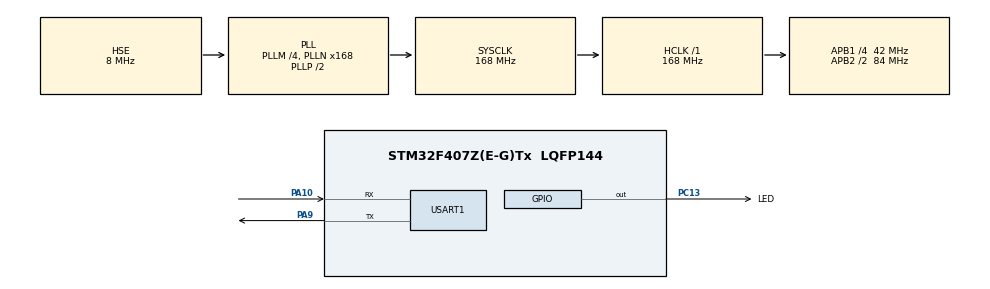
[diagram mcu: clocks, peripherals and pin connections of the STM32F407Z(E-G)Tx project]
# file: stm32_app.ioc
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Mcu.Family=STM32F4
Mcu.Name=STM32F407Z(E-G)Tx
Mcu.Package=LQFP144
NVIC.PriorityGroup=NVIC_PRIORITYGROUP_4
NVIC.USART1_IRQn=true\:5\:0\:true\:false\:true\:true\:true\:true
PA10.Mode=Asynchronous
PA10.Signal=USART1_RX
PA13.Mode=Serial_Wire
PA13.Signal=SYS_JTMS-SWDIO
PA14.Mode=Serial_Wire
PA14.Signal=SYS_JTCK-SWCLK
PA9.Mode=Asynchronous
PA9.Signal=USART1_TX
PC13-ANTI_TAMP.GPIO_Label=LED
PC13-ANTI_TAMP.Signal=GPIO_Output
PC14-OSC32_IN.Mode=LSE-External-Oscillator
PC14-OSC32_IN.Signal=RCC_OSC32_IN
PC15-OSC32_OUT.Mode=LSE-External-Oscillator
PC15-OSC32_OUT.Signal=RCC_OSC32_OUT
PH0-OSC_IN.Mode=HSE-External-Oscillator
PH0-OSC_IN.Signal=RCC_OSC_IN
PH1-OSC_OUT.Mode=HSE-External-Oscillator
PH1-OSC_OUT.Signal=RCC_OSC_OUT
ProjectManager.HeapSize=0x200
ProjectManager.StackSize=0x400
ProjectManager.TargetToolchain=MDK-ARM V5.32
RCC.48MHZClocksFreq_Value=84000000
RCC.AHBFreq_Value=168000000
RCC.APB1CLKDivider=RCC_HCLK_DIV4
RCC.APB1Freq_Value=42000000
RCC.APB1TimFreq_Value=84000000
RCC.APB2CLKDivider=RCC_HCLK_DIV2
RCC.APB2Freq_Value=84000000
RCC.APB2TimFreq_Value=168000000
RCC.CortexFreq_Value=168000000
RCC.HCLKFreq_Value=168000000
RCC.HSE_VALUE=8000000
RCC.HSI_VALUE=16000000
RCC.PLLM=4
RCC.PLLN=168
RCC.PLLSourceVirtual=RCC_PLLSOURCE_HSE
RCC.SYSCLKFreq_VALUE=168000000
RCC.SYSCLKSource=RCC_SYSCLKSOURCE_PLLCLK
RCC.VCOOutputFreq_Value=336000000
USART1.VirtualMode=VM_ASYNC
board=custom

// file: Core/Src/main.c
/* USER CODE BEGIN Header */
/**
  ******************************************************************************
  * @file           : main.c
  * @brief          : Main program body
  ******************************************************************************
  * @attention
  *
  * Copyright (c) 2026 STMicroelectronics.
  * All rights reserved.
  *
  * This software is licensed under terms that can be found in the LICENSE file
  * in the root directory of this software component.
  * If no LICENSE file comes with this software, it is provided AS-IS.
  *
  ******************************************************************************
  */
/* USER CODE END Header */
#include "main.h"
#include "usart.h"
#include "gpio.h"

/* USER CODE BEGIN Includes */
#include <stdio.h>
#include "app_upgrade.h"
/* USER CODE END Includes */

/* USER CODE BEGIN PD */
#define APP_VERSION        "1.3.0"
#define APP_BASE_ADDR      0x08020000UL

#ifndef LOG_ENABLE
    #define LOG_ENABLE  0
#endif
/* USER CODE END PD */

/* USER CODE BEGIN PM */
#if LOG_ENABLE
#define APP_LOG(fmt, ...)   printf("[APP] " fmt "\r\n", ##__VA_ARGS__)
#else
#define APP_LOG(...)       ((void)0)
#endif
/* USER CODE END PM */

/* USER CODE BEGIN PV */
static uint32_t s_last_led_tick;

/* USER CODE END PV */

void SystemClock_Config(void);

int main(void)
{

  /* MCU Configuration--------------------------------------------------------*/

  /* Reset of all peripherals, Initializes the Flash interface and the Systick. */
  HAL_Init();

  /* USER CODE BEGIN Init */
#if !LOG_ENABLE
  app_upgrade_watchdog_start();
#endif

  /* USER CODE END Init */

  /* Configure the system clock */
  SystemClock_Config();

  /* Initialize all configured peripherals */
  MX_GPIO_Init();
  MX_USART1_UART_Init();
  /* USER CODE BEGIN 2 */
#if !LOG_ENABLE
  (void)app_upgrade_init();
#endif
  s_last_led_tick = HAL_GetTick();

  /* USER CODE END 2 */

  /* Infinite loop */
  /* USER CODE BEGIN WHILE */
  APP_LOG("STM32 APP started");
  APP_LOG("Version: %s", APP_VERSION);
  APP_LOG("APP base: 0x%08lX", APP_BASE_ADDR);
	APP_LOG("VTOR     : 0x%08lX",
          (unsigned long)SCB->VTOR);
  while (1)
  {
    /* USER CODE END WHILE */

    /* USER CODE BEGIN 3 */
#if !LOG_ENABLE
    app_upgrade_poll();
#endif
		if ((HAL_GetTick() - s_last_led_tick) >= 500U)
		{
			APP_LOG("LED is blinking...");
			HAL_GPIO_TogglePin(LED_GPIO_Port, LED_Pin);
			s_last_led_tick = HAL_GetTick();
		}
  }
  /* USER CODE END 3 */
}

void SystemClock_Config(void)
{
  RCC_OscInitTypeDef RCC_OscInitStruct = {0};
  RCC_ClkInitTypeDef RCC_ClkInitStruct = {0};

  /** Configure the main internal regulator output voltage
  */
  __HAL_RCC_PWR_CLK_ENABLE();
  __HAL_PWR_VOLTAGESCALING_CONFIG(PWR_REGULATOR_VOLTAGE_SCALE1);

  /** Initializes the RCC Oscillators according to the specified parameters
  * in the RCC_OscInitTypeDef structure.
  */
  RCC_OscInitStruct.OscillatorType = RCC_OSCILLATORTYPE_HSE;
  RCC_OscInitStruct.HSEState = RCC_HSE_ON;
  RCC_OscInitStruct.PLL.PLLState = RCC_PLL_ON;
  RCC_OscInitStruct.PLL.PLLSource = RCC_PLLSOURCE_HSE;
  RCC_OscInitStruct.PLL.PLLM = 4;
  RCC_OscInitStruct.PLL.PLLN = 168;
  RCC_OscInitStruct.PLL.PLLP = RCC_PLLP_DIV2;
  RCC_OscInitStruct.PLL.PLLQ = 4;
  if (HAL_RCC_OscConfig(&RCC_OscInitStruct) != HAL_OK)
  {
    Error_Handler();
  }

  /** Initializes the CPU, AHB and APB buses clocks
  */
  RCC_ClkInitStruct.ClockType = RCC_CLOCKTYPE_HCLK|RCC_CLOCKTYPE_SYSCLK
                              |RCC_CLOCKTYPE_PCLK1|RCC_CLOCKTYPE_PCLK2;
  RCC_ClkInitStruct.SYSCLKSource = RCC_SYSCLKSOURCE_PLLCLK;
  RCC_ClkInitStruct.AHBCLKDivider = RCC_SYSCLK_DIV1;
  RCC_ClkInitStruct.APB1CLKDivider = RCC_HCLK_DIV4;
  RCC_ClkInitStruct.APB2CLKDivider = RCC_HCLK_DIV2;

  if (HAL_RCC_ClockConfig(&RCC_ClkInitStruct, FLASH_LATENCY_5) != HAL_OK)
  {
    Error_Handler();
  }
}

/* USER CODE BEGIN 4 */
int fputc(int ch, FILE *stream)
{
    uint8_t data = (uint8_t)ch;

    (void)stream;

    if (HAL_UART_Transmit(&huart1,
                          &data,
                          1U,
                          10U) != HAL_OK)
    {
        return EOF;
    }

    return ch;
}
/* USER CODE END 4 */

void Error_Handler(void)
{
  __disable_irq();
  while (1)
  {
  }
}
